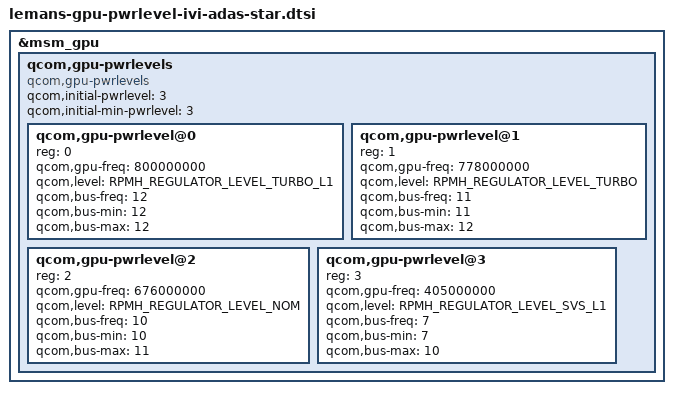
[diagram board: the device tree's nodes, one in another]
&msm_gpu {
	/* Power levels */
	qcom,gpu-pwrlevels {
		#address-cells = <1>;
		#size-cells = <0>;

		compatible = "qcom,gpu-pwrlevels";

		qcom,initial-pwrlevel = <3>;
		qcom,initial-min-pwrlevel = <3>;

		/* Turbo_L1 */
		qcom,gpu-pwrlevel@0 {
			reg = <0>;
			qcom,gpu-freq = <800000000>;
			qcom,level = <RPMH_REGULATOR_LEVEL_TURBO_L1>;

			qcom,bus-freq = <12>;
			qcom,bus-min = <12>;
			qcom,bus-max = <12>;
		};

		/* Turbo */
		qcom,gpu-pwrlevel@1 {
			reg = <1>;
			qcom,gpu-freq = <778000000>;
			qcom,level = <RPMH_REGULATOR_LEVEL_TURBO>;

			qcom,bus-freq = <11>;
			qcom,bus-min = <11>;
			qcom,bus-max = <12>;
		};

		/* Nom */
		qcom,gpu-pwrlevel@2 {
			reg = <2>;
			qcom,gpu-freq = <676000000>;
			qcom,level = <RPMH_REGULATOR_LEVEL_NOM>;

			qcom,bus-freq = <10>;
			qcom,bus-min = <10>;
			qcom,bus-max = <11>;
		};

		/* SVS_L1 */
		qcom,gpu-pwrlevel@3 {
			reg = <3>;
			qcom,gpu-freq = <405000000>;
			qcom,level = <RPMH_REGULATOR_LEVEL_SVS_L1>;

			qcom,bus-freq = <7>;
			qcom,bus-min = <7>;
			qcom,bus-max = <10>;
		};
	};
};
